VERSION "0.1"

NS_ :

BS_ :

BU_ : dash dspace sens_front sens_rear tlb_bat bms_lv

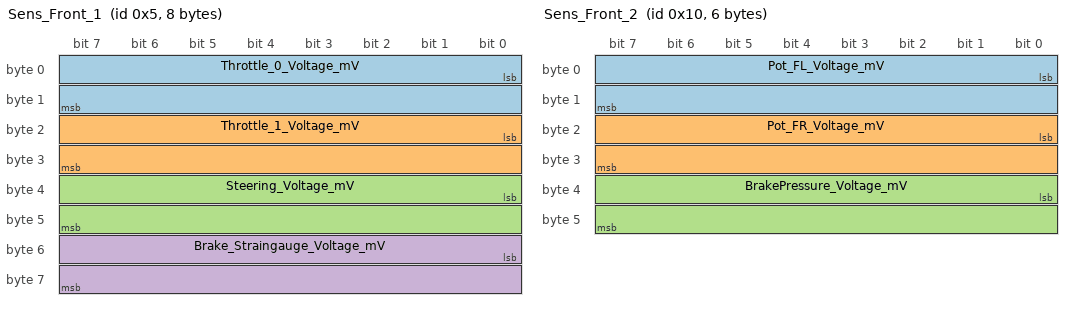
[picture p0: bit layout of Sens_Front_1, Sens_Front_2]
BO_ 5 Sens_Front_1: 8 sens_front
	SG_ Throttle_0_Voltage_mV : 0|16@1+ (1,0) [0|65535] "" dspace
	SG_ Throttle_1_Voltage_mV : 16|16@1+ (1,0) [0|65535] "" dspace
	SG_ Steering_Voltage_mV : 32|16@1+ (1,0) [0|65535] "" dspace
	SG_ Brake_Straingauge_Voltage_mV : 48|16@1+ (1,0) [0|65535] "" dspace

BO_ 16 Sens_Front_2: 6 sens_front
	SG_ Pot_FL_Voltage_mV : 0|16@1+ (1,0) [0|65535] "" dspace
	SG_ Pot_FR_Voltage_mV : 16|16@1+ (1,0) [0|65535] "" dspace
	SG_ BrakePressure_Voltage_mV : 32|16@1+ (1,0) [0|65535] "" dspace

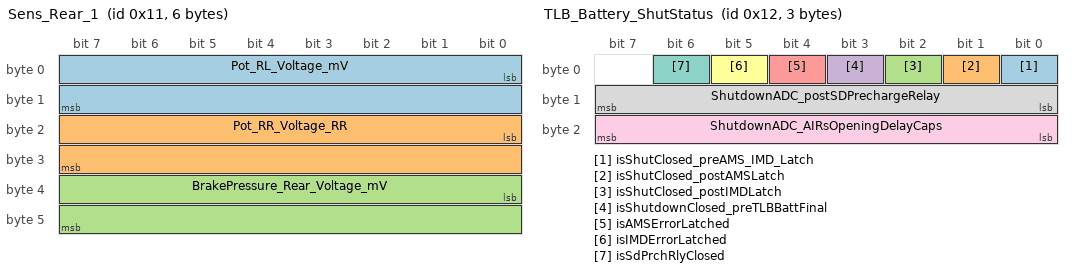
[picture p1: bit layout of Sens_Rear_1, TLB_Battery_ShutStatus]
BO_ 17 Sens_Rear_1: 6 sens_rear
	SG_ Pot_RL_Voltage_mV : 0|16@1+ (1,0) [0|65535] "" dspace
	SG_ Pot_RR_Voltage_RR : 16|16@1+ (1,0) [0|65535] "" dspace
	SG_ BrakePressure_Rear_Voltage_mV : 32|16@1+ (1,0) [0|65535] "" dspace

BO_ 18 TLB_Battery_ShutStatus: 3 tlb_bat
	SG_ isShutClosed_preAMS_IMD_Latch : 0|1@1+ (1,0) [0|1] "" dspace
	SG_ isShutClosed_postAMSLatch : 1|1@1+ (1,0) [0|1] "" dspace
	SG_ isShutClosed_postIMDLatch : 2|1@1+ (1,0) [0|1] "" dspace
	SG_ isShutdownClosed_preTLBBattFinal : 3|1@1+ (1,0) [0|1] "" dspace
	SG_ isAMSErrorLatched : 4|1@1+ (1,0) [0|1] "" dspace
	SG_ isIMDErrorLatched : 5|1@1+ (1,0) [0|1] "" dspace
	SG_ isSdPrchRlyClosed : 6|1@1+ (1,0) [0|1] "" dspace
	SG_ ShutdownADC_postSDPrechargeRelay : 8|8@1+ (0.117,0) [0|255] "V" dspace
	SG_ ShutdownADC_AIRsOpeningDelayCaps : 16|8@1+ (0.117,0) [0|255] "V" dspace

BO_ 19 TLB_Battery_TSALStatus: 3 tlb_bat
	SG_ TSAL_isGreenON : 0|1@1+ (1,0) [0|1] "" dspace
	SG_ TSAL_isAIRPosClosed : 1|1@1+ (1,0) [0|1] "" dspace
	SG_ TSAL_IsAIRNegClosed : 2|1@1+ (1,0) [0|1] "" dspace
	SG_ TSAL_IsRelayPrechargeClosed : 3|1@1+ (1,0) [0|1] "" dspace
	SG_ TSAL_isDCBusOver60V : 4|1@1+ (1,0) [0|1] "" dspace
	SG_ IntentionalState_AIRPos : 5|1@1+ (1,0) [0|1] "" dspace
	SG_ IntentionalState_AIRNeg : 6|1@1+ (1,0) [0|1] "" dspace
	SG_ IntentionalState_RelayPrecharge : 7|1@1+ (1,0) [0|1] "" dspace
	SG_ SCS_Short2GND_AirPos : 8|1@1+ (1,0) [0|1] "" dspace
	SG_ SCS_Short2GND_AirNeg : 9|1@1+ (1,0) [0|1] "" dspace
	SG_ SCS_isAnyShort2GND_Present : 10|1@1+ (1,0) [0|1] "" dspace
	SG_ Imp_isAnyImp_Present : 11|1@1+ (1,0) [0|1] "" dspace
	SG_ Imp_isAIRPosImp_Present : 12|1@1+ (1,0) [0|1] "" dspace
	SG_ Imp_isAIRNegImp_Present : 13|1@1+ (1,0) [0|1] "" dspace
	SG_ Imp_isRelayPrechargeImp_Present : 14|1@1+ (1,0) [0|1] "" dspace
	SG_ Imp_isDCBusVoltageImp_Present : 15|1@1+ (1,0) [0|1] "" dspace
	SG_ Imp_isAnyImp_Latched : 16|1@1+ (1,0) [0|1] "" dspace

BO_ 20 BMSLV_Helo: 8 bms_lv
	SG_ time : 0|64@1+ (1,0) [0|18446744073709552000] "" dspace

BO_ 21 Sens_Front_Helo: 8 bms_lv
	SG_ time : 0|64@1+ (1,0) [0|18446744073709552000] "" dspace

BO_ 22 Sens_Rear_Helo: 8 bms_lv
	SG_ time : 0|64@1+ (1,0) [0|18446744073709552000] "" dspace

BO_ 23 Steering_Helo: 8 bms_lv
	SG_ time : 0|64@1+ (1,0) [0|18446744073709552000] "" dspace

BO_ 24 TLB_Battery_Helo: 8 bms_lv
	SG_ time : 0|64@1+ (1,0) [0|18446744073709552000] "" dspace

BO_ 25 dSpaxe_Helo: 8 bms_lv
	SG_ time : 0|64@1+ (1,0) [0|18446744073709552000] "" dspace

BO_ 37 dSpace_RTD_ACK: 1 dspace
	SG_ RTD_FSM_STATE : 0|8@1- (1,0) [-1|6] "" dash

BO_ 38 Steering_RTD: 1 dash
	SG_ RTD_CMD : 0|8@1+ (1,0) [0|255] "" dspace

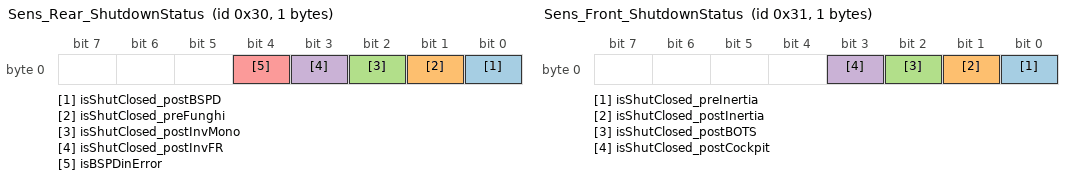
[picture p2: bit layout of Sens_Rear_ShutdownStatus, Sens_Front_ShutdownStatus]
BO_ 48 Sens_Rear_ShutdownStatus: 1 sens_rear
	SG_ isShutClosed_postBSPD : 0|1@1- (1,0) [0|1] "" dspace
	SG_ isShutClosed_preFunghi : 1|1@1- (1,0) [0|1] "" dspace
	SG_ isShutClosed_postInvMono : 2|1@1- (1,0) [0|1] "" dspace
	SG_ isShutClosed_postInvFR : 3|1@1- (1,0) [0|1] "" dspace
	SG_ isBSPDinError : 4|1@1- (1,0) [0|1] "" dspace

BO_ 49 Sens_Front_ShutdownStatus: 1 sens_front
	SG_ isShutClosed_preInertia : 0|1@1- (1,0) [0|1] "" dspace
	SG_ isShutClosed_postInertia : 1|1@1- (1,0) [0|1] "" dspace
	SG_ isShutClosed_postBOTS : 2|1@1- (1,0) [0|1] "" dspace
	SG_ isShutClosed_postCockpit : 3|1@1- (1,0) [0|1] "" dspace

BO_ 255 BMSLV_RelayOverride: 2 dspace
	SG_ password : 0|15@1+ (1,0) [0|65535] "" bms_lv
	SG_ close_relay : 15|1@1+ (1,0) [0|1] "" bms_lv

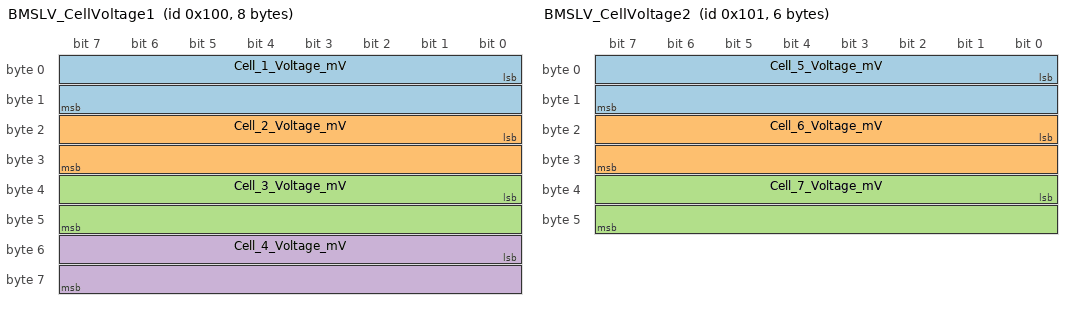
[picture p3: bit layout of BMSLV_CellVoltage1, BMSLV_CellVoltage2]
BO_ 256 BMSLV_CellVoltage1: 8 bms_lv
	SG_ Cell_1_Voltage_mV : 0|16@1+ (0.038,2000) [0|2490.33] "" dspace
	SG_ Cell_2_Voltage_mV : 16|16@1+ (0.038,2000) [0|2490.33] "" dspace
	SG_ Cell_3_Voltage_mV : 32|16@1+ (0.038,2000) [0|2490.33] "" dspace
	SG_ Cell_4_Voltage_mV : 48|16@1+ (0.038,2000) [0|2490.33] "" dspace

BO_ 257 BMSLV_CellVoltage2: 6 bms_lv
	SG_ Cell_5_Voltage_mV : 0|16@1+ (0.038,2000) [0|2490.33] "" dspace
	SG_ Cell_6_Voltage_mV : 16|16@1+ (0.038,2000) [0|2490.33] "" dspace
	SG_ Cell_7_Voltage_mV : 32|16@1+ (0.038,2000) [0|2490.33] "" dspace

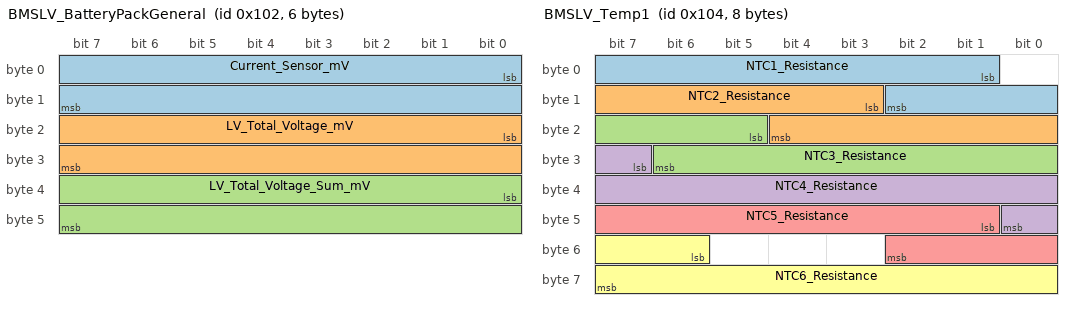
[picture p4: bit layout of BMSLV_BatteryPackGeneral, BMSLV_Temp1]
BO_ 258 BMSLV_BatteryPackGeneral: 6 bms_lv
	SG_ Current_Sensor_mV : 0|16@1+ (0.076,0) [0|4980.66] "" dspace
	SG_ LV_Total_Voltage_mV : 16|16@1+ (0.267,14000) [0|17497.845] "" dspace
	SG_ LV_Total_Voltage_Sum_mV : 32|16@1+ (0.267,14000) [0|17497.845] "" dspace

BO_ 259 BMSLV_Status: 4 bms_lv
	SG_ isRelayOpen : 0|1@1+ (1,0) [0|1] "" dspace
	SG_ cell1_OV : 1|1@1+ (1,0) [0|1] "" dspace
	SG_ cell2_OV : 2|1@1+ (1,0) [0|1] "" dspace
	SG_ cell3_OV : 3|1@1+ (1,0) [0|1] "" dspace
	SG_ cell4_OV : 4|1@1+ (1,0) [0|1] "" dspace
	SG_ cell5_OV : 5|1@1+ (1,0) [0|1] "" dspace
	SG_ cell6_OV : 6|1@1+ (1,0) [0|1] "" dspace
	SG_ cell7_OV : 7|1@1+ (1,0) [0|1] "" dspace
	SG_ cell1_UV : 8|1@1+ (1,0) [0|1] "" dspace
	SG_ cell2_UV : 9|1@1+ (1,0) [0|1] "" dspace
	SG_ cell3_UV : 10|1@1+ (1,0) [0|1] "" dspace
	SG_ cell4_UV : 11|1@1+ (1,0) [0|1] "" dspace
	SG_ cell5_UV : 12|1@1+ (1,0) [0|1] "" dspace
	SG_ cell6_UV : 13|1@1+ (1,0) [0|1] "" dspace
	SG_ cell7_UV : 14|1@1+ (1,0) [0|1] "" dspace
	SG_ temp1_OT : 15|1@1+ (1,0) [0|1] "" dspace
	SG_ temp2_OT : 16|1@1+ (1,0) [0|1] "" dspace
	SG_ temp3_OT : 17|1@1+ (1,0) [0|1] "" dspace
	SG_ temp4_OT : 18|1@1+ (1,0) [0|1] "" dspace
	SG_ temp5_OT : 19|1@1+ (1,0) [0|1] "" dspace
	SG_ temp6_OT : 20|1@1+ (1,0) [0|1] "" dspace
	SG_ temp7_OT : 21|1@1+ (1,0) [0|1] "" dspace
	SG_ temp8_OT : 22|1@1+ (1,0) [0|1] "" dspace
	SG_ temp9_OT : 23|1@1+ (1,0) [0|1] "" dspace
	SG_ temp10_OT : 24|1@1+ (1,0) [0|1] "" dspace
	SG_ temp11_OT : 25|1@1+ (1,0) [0|1] "" dspace
	SG_ temp12_OT : 26|1@1+ (1,0) [0|1] "" dspace

BO_ 260 BMSLV_Temp1: 8 bms_lv
	SG_ NTC1_Resistance : 1|10@1+ (31.25,1000) [0|31968.75] "Ohm" dspace
	SG_ NTC2_Resistance : 11|10@1+ (31.25,1000) [0|31968.75] "Ohm" dspace
	SG_ NTC3_Resistance : 21|10@1+ (31.25,1000) [0|31968.75] "Ohm" dspace
	SG_ NTC4_Resistance : 31|10@1+ (31.25,1000) [0|31968.75] "Ohm" dspace
	SG_ NTC5_Resistance : 41|10@1+ (31.25,1000) [0|31968.75] "Ohm" dspace
	SG_ NTC6_Resistance : 54|10@1+ (31.25,1000) [0|31968.75] "Ohm" dspace

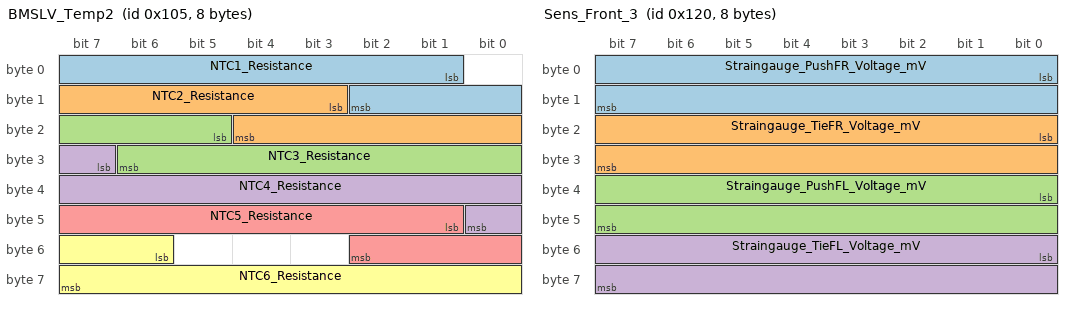
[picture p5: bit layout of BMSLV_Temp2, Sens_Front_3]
BO_ 261 BMSLV_Temp2: 8 bms_lv
	SG_ NTC1_Resistance : 1|10@1+ (31.25,1000) [0|31968.75] "Ohm" dspace
	SG_ NTC2_Resistance : 11|10@1+ (31.25,1000) [0|31968.75] "Ohm" dspace
	SG_ NTC3_Resistance : 21|10@1+ (31.25,1000) [0|31968.75] "Ohm" dspace
	SG_ NTC4_Resistance : 31|10@1+ (31.25,1000) [0|31968.75] "Ohm" dspace
	SG_ NTC5_Resistance : 41|10@1+ (31.25,1000) [0|31968.75] "Ohm" dspace
	SG_ NTC6_Resistance : 54|10@1+ (31.25,1000) [0|31968.75] "Ohm" dspace

BO_ 288 Sens_Front_3: 8 sens_front
	SG_ Straingauge_PushFR_Voltage_mV : 0|16@1+ (1,0) [0|65535] "" dspace
	SG_ Straingauge_TieFR_Voltage_mV : 16|16@1+ (1,0) [0|65535] "" dspace
	SG_ Straingauge_PushFL_Voltage_mV : 32|16@1+ (1,0) [0|65535] "" dspace
	SG_ Straingauge_TieFL_Voltage_mV : 48|16@1+ (1,0) [0|65535] "" dspace

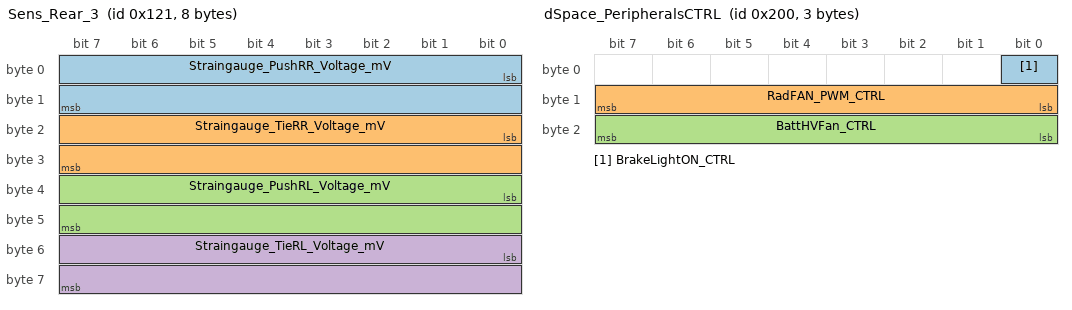
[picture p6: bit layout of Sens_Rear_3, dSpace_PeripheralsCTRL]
BO_ 289 Sens_Rear_3: 8 sens_rear
	SG_ Straingauge_PushRR_Voltage_mV : 0|16@1+ (1,0) [0|65535] "" dspace
	SG_ Straingauge_TieRR_Voltage_mV : 16|16@1+ (1,0) [0|65535] "" dspace
	SG_ Straingauge_PushRL_Voltage_mV : 32|16@1+ (1,0) [0|65535] "" dspace
	SG_ Straingauge_TieRL_Voltage_mV : 48|16@1+ (1,0) [0|65535] "" dspace

BO_ 512 dSpace_PeripheralsCTRL: 3 dspace
	SG_ BrakeLightON_CTRL : 0|1@1- (1,0) [0|1] "" dash
	SG_ RadFAN_PWM_CTRL : 8|8@1+ (1,0) [0|255] "" dash
	SG_ BattHVFan_CTRL : 16|8@1+ (1,0) [0|255] "" dash

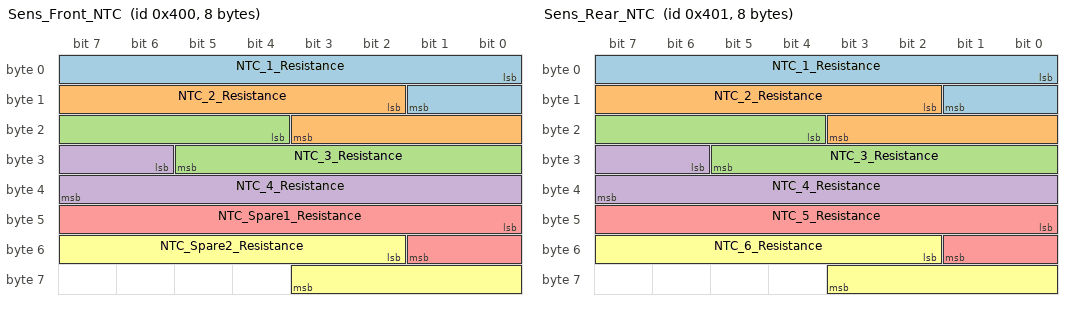
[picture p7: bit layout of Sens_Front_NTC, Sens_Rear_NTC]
BO_ 1024 Sens_Front_NTC: 8 sens_front
	SG_ NTC_1_Resistance : 0|10@1+ (31.25,1000) [0|31968.75] "Ohm" dspace
	SG_ NTC_2_Resistance : 10|10@1+ (31.25,1000) [0|31968.75] "Ohm" dspace
	SG_ NTC_3_Resistance : 20|10@1+ (31.25,1000) [0|31968.75] "Ohm" dspace
	SG_ NTC_4_Resistance : 30|10@1+ (31.25,1000) [0|31968.75] "Ohm" dspace
	SG_ NTC_Spare1_Resistance : 40|10@1+ (31.25,1000) [0|31968.75] "Ohm" dspace
	SG_ NTC_Spare2_Resistance : 50|10@1+ (31.25,1000) [0|31968.75] "Ohm" dspace

BO_ 1025 Sens_Rear_NTC: 8 sens_rear
	SG_ NTC_1_Resistance : 0|10@1+ (31.25,1000) [0|31968.75] "Ohm" dspace
	SG_ NTC_2_Resistance : 10|10@1+ (31.25,1000) [0|31968.75] "Ohm" dspace
	SG_ NTC_3_Resistance : 20|10@1+ (31.25,1000) [0|31968.75] "Ohm" dspace
	SG_ NTC_4_Resistance : 30|10@1+ (31.25,1000) [0|31968.75] "Ohm" dspace
	SG_ NTC_5_Resistance : 40|10@1+ (31.25,1000) [0|31968.75] "Ohm" dspace
	SG_ NTC_6_Resistance : 50|10@1+ (31.25,1000) [0|31968.75] "Ohm" dspace

BO_ 1026 Sens_Rear_2: 4 sens_rear
	SG_ CoolingPressure_DX_Voltage_mV : 0|16@1+ (1,0) [0|65535] "" dspace
	SG_ CoolingPressure_SX_Voltage_mV : 16|16@1+ (1,0) [0|65535] "" dspace

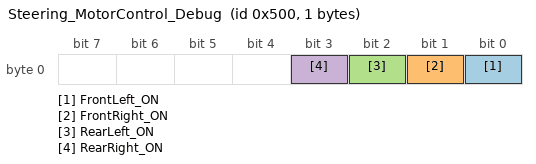
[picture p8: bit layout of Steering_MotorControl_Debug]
BO_ 1280 Steering_MotorControl_Debug: 1 dash
	SG_ FrontLeft_ON : 0|1@1- (1,0) [0|1] "" dspace
	SG_ FrontRight_ON : 1|1@1- (1,0) [0|1] "" dspace
	SG_ RearLeft_ON : 2|1@1- (1,0) [0|1] "" dspace
	SG_ RearRight_ON : 3|1@1- (1,0) [0|1] "" dspace

CM_ BU_ dspace "automotive ECU";
CM_ BU_ sens_front "sensorboard front ECU";
CM_ BU_ sens_rear "sensorboard rear ECU";
CM_ BU_ tlb_bat "tsal-latch-board battery ECU";
CM_ BU_ bms_lv "battery-management-system low-voltage";
CM_ BU_ dash "dashboard ECU";
CM_ BO_ 22 "(period: 10 ms)";
CM_ BO_ 289 "(period: 10 ms)";
CM_ BO_ 38 "(period: 500 ms)";
CM_ BO_ 19 "(period: 100 ms)";
CM_ BO_ 16 "(period: 10 ms)";
CM_ BO_ 256 "(period: 100 ms)";
CM_ BO_ 260 "(period: 2000 ms)";
CM_ BO_ 1025 "(period: 10 ms)";
CM_ BO_ 288 "(period: 10 ms)";
CM_ BO_ 1024 "(period: 10 ms)";
CM_ BO_ 17 "(period: 10 ms)";
CM_ BO_ 18 "(period: 100 ms)";
CM_ BO_ 258 "(period: 100 ms)";
CM_ BO_ 259 "(period: 100 ms)";
CM_ BO_ 1026 "(period: 10 ms)";
CM_ BO_ 5 "(period: 10 ms)";
CM_ BO_ 49 "(period: 10 ms)";
CM_ BO_ 261 "(period: 2000 ms)";
CM_ BO_ 48 "(period: 10 ms)";
CM_ BO_ 257 "(period: 100 ms)";

BA_DEF_ BO_ "GenMsgSendType" ENUM "NoMsgSendType","Cyclic","IfActive","CyclicIfActive","NotUsed";
BA_DEF_ SG_ "GenSigSendType" ENUM "NoSigSendType","Cyclic","OnWrite","OnWriteWithRepetition","OnChange","OnChangeWithRepetition","IfActive","IfActiveWithRepetition","NotUsed";
BA_DEF_DEF_ "GenMsgSendType" "NoMsgSendType";
BA_DEF_DEF_ "GenSigSendType" "NoSigSendType";
